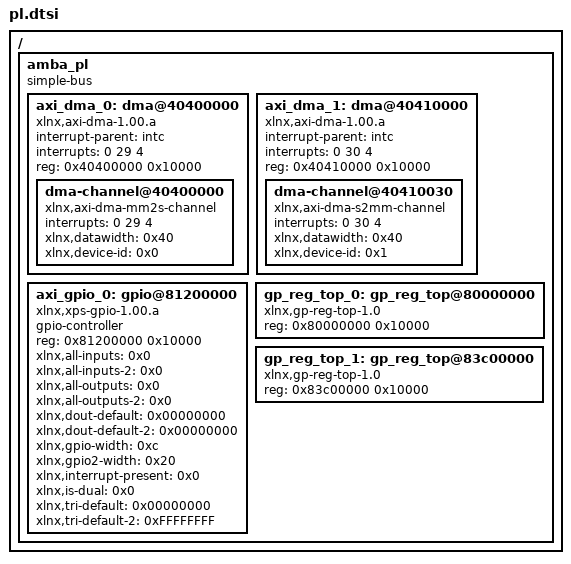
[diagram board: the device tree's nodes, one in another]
/*
 * CAUTION: This file is automatically generated by Xilinx.
 * Version: HSI 2015.4
 * Today is: Mon Jul  1 05:15:52 2019
*/


/ {
	amba_pl: amba_pl {
		#address-cells = <1>;
		#size-cells = <1>;
		compatible = "simple-bus";
		ranges ;
		axi_dma_0: dma@40400000 {
			#dma-cells = <1>;
			compatible = "xlnx,axi-dma-1.00.a";
			interrupt-parent = <&intc>;
			interrupts = <0 29 4>;
			reg = <0x40400000 0x10000>;
			dma-channel@40400000 {
				compatible = "xlnx,axi-dma-mm2s-channel";
				interrupts = <0 29 4>;
				xlnx,datawidth = <0x40>;
				xlnx,device-id = <0x0>;
			};
		};
		axi_dma_1: dma@40410000 {
			#dma-cells = <1>;
			compatible = "xlnx,axi-dma-1.00.a";
			interrupt-parent = <&intc>;
			interrupts = <0 30 4>;
			reg = <0x40410000 0x10000>;
			dma-channel@40410030 {
				compatible = "xlnx,axi-dma-s2mm-channel";
				interrupts = <0 30 4>;
				xlnx,datawidth = <0x40>;
				xlnx,device-id = <0x1>;
			};
		};
		axi_gpio_0: gpio@81200000 {
			#gpio-cells = <2>;
			compatible = "xlnx,xps-gpio-1.00.a";
			gpio-controller ;
			reg = <0x81200000 0x10000>;
			xlnx,all-inputs = <0x0>;
			xlnx,all-inputs-2 = <0x0>;
			xlnx,all-outputs = <0x0>;
			xlnx,all-outputs-2 = <0x0>;
			xlnx,dout-default = <0x00000000>;
			xlnx,dout-default-2 = <0x00000000>;
			xlnx,gpio-width = <0xc>;
			xlnx,gpio2-width = <0x20>;
			xlnx,interrupt-present = <0x0>;
			xlnx,is-dual = <0x0>;
			xlnx,tri-default = <0x00000000>;
			xlnx,tri-default-2 = <0xFFFFFFFF>;
		};
		gp_reg_top_0: gp_reg_top@80000000 {
			compatible = "xlnx,gp-reg-top-1.0";
			reg = <0x80000000 0x10000>;
		};
		gp_reg_top_1: gp_reg_top@83c00000 {
			compatible = "xlnx,gp-reg-top-1.0";
			reg = <0x83c00000 0x10000>;
		};
	};
};
